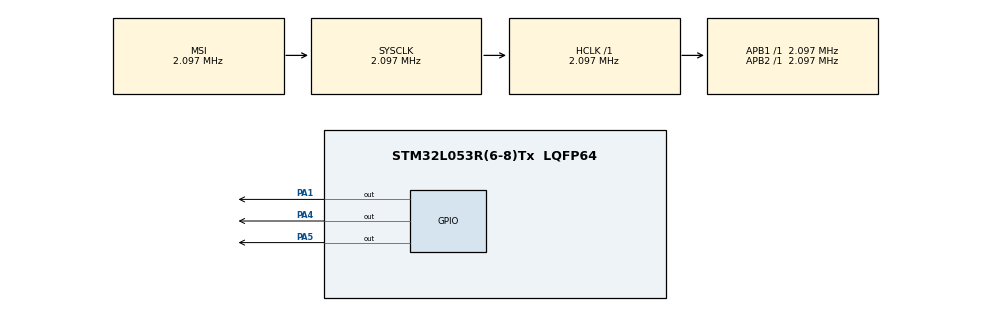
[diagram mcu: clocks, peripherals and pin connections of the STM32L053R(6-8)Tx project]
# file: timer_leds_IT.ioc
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Mcu.Family=STM32L0
Mcu.Name=STM32L053R(6-8)Tx
Mcu.Package=LQFP64
NVIC.TIM21_IRQn=true\:0\:0\:false\:false\:true\:true\:true\:true
NVIC.TIM22_IRQn=true\:0\:0\:false\:false\:true\:true\:true\:true
NVIC.TIM6_DAC_IRQn=true\:0\:0\:false\:false\:true\:true\:true\:true
PA1.Signal=GPIO_Output
PA4.Signal=GPIO_Output
PA5.Signal=GPIO_Output
ProjectManager.HeapSize=0x200
ProjectManager.StackSize=0x400
ProjectManager.TargetToolchain=STM32CubeIDE
RCC.AHBFreq_Value=2097000
RCC.APB1Freq_Value=2097000
RCC.APB1TimFreq_Value=2097000
RCC.APB2Freq_Value=2097000
RCC.APB2TimFreq_Value=2097000
RCC.HCLKFreq_Value=2097000
RCC.HSE_VALUE=8000000
RCC.HSI16_VALUE=16000000
RCC.HSI48_VALUE=48000000
RCC.HSI_VALUE=16000000
RCC.LSE_VALUE=32768
RCC.MSI_VALUE=2097000
RCC.SYSCLKFreq_VALUE=2097000
RCC.VCOOutputFreq_Value=48000000
TIM21.Period=999
TIM21.Prescaler=1999
TIM22.Period=999
TIM22.Prescaler=3999
TIM6.Period=999
TIM6.Prescaler=999
VP_TIM21_VS_ClockSourceINT.Mode=Internal
VP_TIM22_VS_ClockSourceINT.Mode=Internal
VP_TIM6_VS_ClockSourceINT.Mode=Enable_Timer
board=custom

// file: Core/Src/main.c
/* USER CODE BEGIN Header */
/**
  ******************************************************************************
  * @file           : main.c
  * @brief          : Main program body
  ******************************************************************************
  * @attention
  *
  * Copyright (c) 2023 STMicroelectronics.
  * All rights reserved.
  *
  * This software is licensed under terms that can be found in the LICENSE file
  * in the root directory of this software component.
  * If no LICENSE file comes with this software, it is provided AS-IS.
  *
  ******************************************************************************
  */
/* USER CODE END Header */
#include "main.h"

TIM_HandleTypeDef htim6;
TIM_HandleTypeDef htim21;
TIM_HandleTypeDef htim22;

void SystemClock_Config(void);
static void MX_GPIO_Init(void);
static void MX_TIM6_Init(void);
static void MX_TIM21_Init(void);
static void MX_TIM22_Init(void);

/* USER CODE BEGIN 0 */

  void HAL_TIM_PeriodElapsedCallback(TIM_HandleTypeDef *htim) {
	// 2 sec
	if (htim == &htim22) {
		HAL_GPIO_TogglePin(GPIOA, GPIO_PIN_4);
	}
	// 1 sec
    if (htim == &htim21) {
        HAL_GPIO_TogglePin(GPIOA, GPIO_PIN_1);
    }
    // 0.5 sec
    if (htim == &htim6) {
    	HAL_GPIO_TogglePin(GPIOA, GPIO_PIN_5);
    }
  }
/* USER CODE END 0 */

int main(void)
{

  /* MCU Configuration--------------------------------------------------------*/

  /* Reset of all peripherals, Initializes the Flash interface and the Systick. */
  HAL_Init();

  /* Configure the system clock */
  SystemClock_Config();

  /* Initialize all configured peripherals */
  MX_GPIO_Init();
  MX_TIM6_Init();
  MX_TIM21_Init();
  MX_TIM22_Init();
  /* USER CODE BEGIN 2 */
  HAL_TIM_Base_Start_IT(&htim6);
  HAL_TIM_Base_Start_IT(&htim21);
  HAL_TIM_Base_Start_IT(&htim22);

  /* USER CODE END 2 */

  /* Infinite loop */
  while (1)
  {

  }
}

void SystemClock_Config(void)
{
  RCC_OscInitTypeDef RCC_OscInitStruct = {0};
  RCC_ClkInitTypeDef RCC_ClkInitStruct = {0};

  /** Configure the main internal regulator output voltage
  */
  __HAL_PWR_VOLTAGESCALING_CONFIG(PWR_REGULATOR_VOLTAGE_SCALE1);

  /** Initializes the RCC Oscillators according to the specified parameters
  * in the RCC_OscInitTypeDef structure.
  */
  RCC_OscInitStruct.OscillatorType = RCC_OSCILLATORTYPE_MSI;
  RCC_OscInitStruct.MSIState = RCC_MSI_ON;
  RCC_OscInitStruct.MSICalibrationValue = 0;
  RCC_OscInitStruct.MSIClockRange = RCC_MSIRANGE_5;
  RCC_OscInitStruct.PLL.PLLState = RCC_PLL_NONE;
  if (HAL_RCC_OscConfig(&RCC_OscInitStruct) != HAL_OK)
  {
    Error_Handler();
  }

  /** Initializes the CPU, AHB and APB buses clocks
  */
  RCC_ClkInitStruct.ClockType = RCC_CLOCKTYPE_HCLK|RCC_CLOCKTYPE_SYSCLK
                              |RCC_CLOCKTYPE_PCLK1|RCC_CLOCKTYPE_PCLK2;
  RCC_ClkInitStruct.SYSCLKSource = RCC_SYSCLKSOURCE_MSI;
  RCC_ClkInitStruct.AHBCLKDivider = RCC_SYSCLK_DIV1;
  RCC_ClkInitStruct.APB1CLKDivider = RCC_HCLK_DIV1;
  RCC_ClkInitStruct.APB2CLKDivider = RCC_HCLK_DIV1;

  if (HAL_RCC_ClockConfig(&RCC_ClkInitStruct, FLASH_LATENCY_0) != HAL_OK)
  {
    Error_Handler();
  }
}

static void MX_TIM6_Init(void)
{

  TIM_MasterConfigTypeDef sMasterConfig = {0};

  htim6.Instance = TIM6;
  htim6.Init.Prescaler = 999;
  htim6.Init.CounterMode = TIM_COUNTERMODE_UP;
  htim6.Init.Period = 999;
  htim6.Init.AutoReloadPreload = TIM_AUTORELOAD_PRELOAD_DISABLE;
  if (HAL_TIM_Base_Init(&htim6) != HAL_OK)
  {
    Error_Handler();
  }
  sMasterConfig.MasterOutputTrigger = TIM_TRGO_RESET;
  sMasterConfig.MasterSlaveMode = TIM_MASTERSLAVEMODE_DISABLE;
  if (HAL_TIMEx_MasterConfigSynchronization(&htim6, &sMasterConfig) != HAL_OK)
  {
    Error_Handler();
  }

}

static void MX_TIM21_Init(void)
{

  TIM_ClockConfigTypeDef sClockSourceConfig = {0};
  TIM_MasterConfigTypeDef sMasterConfig = {0};

  htim21.Instance = TIM21;
  htim21.Init.Prescaler = 1999;
  htim21.Init.CounterMode = TIM_COUNTERMODE_UP;
  htim21.Init.Period = 999;
  htim21.Init.ClockDivision = TIM_CLOCKDIVISION_DIV1;
  htim21.Init.AutoReloadPreload = TIM_AUTORELOAD_PRELOAD_DISABLE;
  if (HAL_TIM_Base_Init(&htim21) != HAL_OK)
  {
    Error_Handler();
  }
  sClockSourceConfig.ClockSource = TIM_CLOCKSOURCE_INTERNAL;
  if (HAL_TIM_ConfigClockSource(&htim21, &sClockSourceConfig) != HAL_OK)
  {
    Error_Handler();
  }
  sMasterConfig.MasterOutputTrigger = TIM_TRGO_RESET;
  sMasterConfig.MasterSlaveMode = TIM_MASTERSLAVEMODE_DISABLE;
  if (HAL_TIMEx_MasterConfigSynchronization(&htim21, &sMasterConfig) != HAL_OK)
  {
    Error_Handler();
  }

}

static void MX_TIM22_Init(void)
{

  TIM_ClockConfigTypeDef sClockSourceConfig = {0};
  TIM_MasterConfigTypeDef sMasterConfig = {0};

  htim22.Instance = TIM22;
  htim22.Init.Prescaler = 3999;
  htim22.Init.CounterMode = TIM_COUNTERMODE_UP;
  htim22.Init.Period = 999;
  htim22.Init.ClockDivision = TIM_CLOCKDIVISION_DIV1;
  htim22.Init.AutoReloadPreload = TIM_AUTORELOAD_PRELOAD_DISABLE;
  if (HAL_TIM_Base_Init(&htim22) != HAL_OK)
  {
    Error_Handler();
  }
  sClockSourceConfig.ClockSource = TIM_CLOCKSOURCE_INTERNAL;
  if (HAL_TIM_ConfigClockSource(&htim22, &sClockSourceConfig) != HAL_OK)
  {
    Error_Handler();
  }
  sMasterConfig.MasterOutputTrigger = TIM_TRGO_RESET;
  sMasterConfig.MasterSlaveMode = TIM_MASTERSLAVEMODE_DISABLE;
  if (HAL_TIMEx_MasterConfigSynchronization(&htim22, &sMasterConfig) != HAL_OK)
  {
    Error_Handler();
  }

}

static void MX_GPIO_Init(void)
{
  GPIO_InitTypeDef GPIO_InitStruct = {0};

  /* GPIO Ports Clock Enable */
  __HAL_RCC_GPIOA_CLK_ENABLE();

  /*Configure GPIO pin Output Level */
  HAL_GPIO_WritePin(GPIOA, GPIO_PIN_1|GPIO_PIN_4|GPIO_PIN_5, GPIO_PIN_RESET);

  /*Configure GPIO pins : PA1 PA4 PA5 */
  GPIO_InitStruct.Pin = GPIO_PIN_1|GPIO_PIN_4|GPIO_PIN_5;
  GPIO_InitStruct.Mode = GPIO_MODE_OUTPUT_PP;
  GPIO_InitStruct.Pull = GPIO_NOPULL;
  GPIO_InitStruct.Speed = GPIO_SPEED_FREQ_LOW;
  HAL_GPIO_Init(GPIOA, &GPIO_InitStruct);

}

void Error_Handler(void)
{
  __disable_irq();
  while (1)
  {
  }
}
